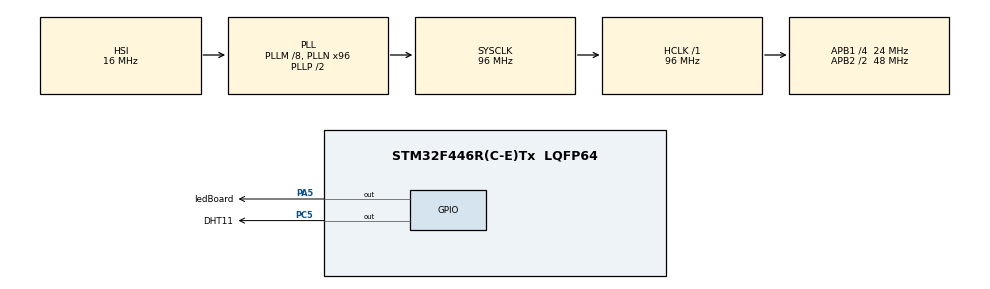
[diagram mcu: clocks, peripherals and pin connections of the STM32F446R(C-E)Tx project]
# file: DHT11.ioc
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Mcu.Family=STM32F4
Mcu.Name=STM32F446R(C-E)Tx
Mcu.Package=LQFP64
NVIC.PriorityGroup=NVIC_PRIORITYGROUP_4
NVIC.TIM6_DAC_IRQn=true\:0\:0\:false\:false\:true\:true\:true\:true
PA13.Mode=Serial_Wire
PA13.Signal=SYS_JTMS-SWDIO
PA14.Mode=Serial_Wire
PA14.Signal=SYS_JTCK-SWCLK
PA5.GPIO_Label=ledBoard
PA5.Signal=GPIO_Output
PC5.GPIO_Label=DHT11
PC5.GPIO_Speed=GPIO_SPEED_FREQ_VERY_HIGH
PC5.PinState=GPIO_PIN_RESET
PC5.Signal=GPIO_Output
ProjectManager.HeapSize=0x200
ProjectManager.StackSize=0x400
ProjectManager.TargetToolchain=STM32CubeIDE
RCC.AHBFreq_Value=96000000
RCC.APB1CLKDivider=RCC_HCLK_DIV4
RCC.APB1Freq_Value=24000000
RCC.APB1TimFreq_Value=48000000
RCC.APB2CLKDivider=RCC_HCLK_DIV2
RCC.APB2Freq_Value=48000000
RCC.APB2TimFreq_Value=96000000
RCC.CortexFreq_Value=96000000
RCC.HCLKFreq_Value=96000000
RCC.PLLM=8
RCC.PLLN=96
RCC.SYSCLKFreq_VALUE=96000000
RCC.SYSCLKSource=RCC_SYSCLKSOURCE_PLLCLK
RCC.USBFreq_Value=96000000
RCC.VCOOutputFreq_Value=192000000
TIM6.Period=1200-1
TIM6.Prescaler=48000-1
VP_TIM6_VS_ClockSourceINT.Mode=Enable_Timer
board=custom

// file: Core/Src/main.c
/* USER CODE BEGIN Header */
/**
 ******************************************************************************
 * @file           : main.c
 * @brief          : Main program body
 ******************************************************************************
 * @attention
 *
 * Copyright (c) 2022 STMicroelectronics.
 * All rights reserved.
 *
 * This software is licensed under terms that can be found in the LICENSE file
 * in the root directory of this software component.
 * If no LICENSE file comes with this software, it is provided AS-IS.
 *
 ******************************************************************************
 */
/* USER CODE END Header */
#include "main.h"

/* USER CODE BEGIN Includes */
#include "DHT11.h"
/* USER CODE END Includes */

TIM_HandleTypeDef htim6;

/* USER CODE BEGIN PV */
uint8_t temp, hum; // creo dos variables para leer los datos de T° y H

/* USER CODE END PV */

void SystemClock_Config(void);
static void MX_GPIO_Init(void);
static void MX_TIM6_Init(void);

int main(void)
{

  /* MCU Configuration--------------------------------------------------------*/

  /* Reset of all peripherals, Initializes the Flash interface and the Systick. */
  HAL_Init();

  /* Configure the system clock */
  SystemClock_Config();

  /* Initialize all configured peripherals */
  MX_GPIO_Init();
  MX_TIM6_Init();
  /* USER CODE BEGIN 2 */

  HAL_TIM_Base_Start_IT(&htim6);

  /* USER CODE END 2 */

  /* Infinite loop */
  /* USER CODE BEGIN WHILE */
	while (1) {

		if(hum>50){
			HAL_GPIO_TogglePin(ledBoard_GPIO_Port, ledBoard_Pin);
			HAL_Delay(250);
		}

    /* USER CODE END WHILE */

	}
}

void SystemClock_Config(void)
{
  RCC_OscInitTypeDef RCC_OscInitStruct = {0};
  RCC_ClkInitTypeDef RCC_ClkInitStruct = {0};

  /** Configure the main internal regulator output voltage
  */
  __HAL_RCC_PWR_CLK_ENABLE();
  __HAL_PWR_VOLTAGESCALING_CONFIG(PWR_REGULATOR_VOLTAGE_SCALE3);

  /** Initializes the RCC Oscillators according to the specified parameters
  * in the RCC_OscInitTypeDef structure.
  */
  RCC_OscInitStruct.OscillatorType = RCC_OSCILLATORTYPE_HSI;
  RCC_OscInitStruct.HSIState = RCC_HSI_ON;
  RCC_OscInitStruct.HSICalibrationValue = RCC_HSICALIBRATION_DEFAULT;
  RCC_OscInitStruct.PLL.PLLState = RCC_PLL_ON;
  RCC_OscInitStruct.PLL.PLLSource = RCC_PLLSOURCE_HSI;
  RCC_OscInitStruct.PLL.PLLM = 8;
  RCC_OscInitStruct.PLL.PLLN = 96;
  RCC_OscInitStruct.PLL.PLLP = RCC_PLLP_DIV2;
  RCC_OscInitStruct.PLL.PLLQ = 2;
  RCC_OscInitStruct.PLL.PLLR = 2;
  if (HAL_RCC_OscConfig(&RCC_OscInitStruct) != HAL_OK)
  {
    Error_Handler();
  }

  /** Initializes the CPU, AHB and APB buses clocks
  */
  RCC_ClkInitStruct.ClockType = RCC_CLOCKTYPE_HCLK|RCC_CLOCKTYPE_SYSCLK
                              |RCC_CLOCKTYPE_PCLK1|RCC_CLOCKTYPE_PCLK2;
  RCC_ClkInitStruct.SYSCLKSource = RCC_SYSCLKSOURCE_PLLCLK;
  RCC_ClkInitStruct.AHBCLKDivider = RCC_SYSCLK_DIV1;
  RCC_ClkInitStruct.APB1CLKDivider = RCC_HCLK_DIV4;
  RCC_ClkInitStruct.APB2CLKDivider = RCC_HCLK_DIV2;

  if (HAL_RCC_ClockConfig(&RCC_ClkInitStruct, FLASH_LATENCY_3) != HAL_OK)
  {
    Error_Handler();
  }
}

static void MX_TIM6_Init(void)
{

  TIM_MasterConfigTypeDef sMasterConfig = {0};

  htim6.Instance = TIM6;
  htim6.Init.Prescaler = 48000-1;
  htim6.Init.CounterMode = TIM_COUNTERMODE_UP;
  htim6.Init.Period = 1200-1;
  htim6.Init.AutoReloadPreload = TIM_AUTORELOAD_PRELOAD_DISABLE;
  if (HAL_TIM_Base_Init(&htim6) != HAL_OK)
  {
    Error_Handler();
  }
  sMasterConfig.MasterOutputTrigger = TIM_TRGO_RESET;
  sMasterConfig.MasterSlaveMode = TIM_MASTERSLAVEMODE_DISABLE;
  if (HAL_TIMEx_MasterConfigSynchronization(&htim6, &sMasterConfig) != HAL_OK)
  {
    Error_Handler();
  }

}

static void MX_GPIO_Init(void)
{
  GPIO_InitTypeDef GPIO_InitStruct = {0};

  /* GPIO Ports Clock Enable */
  __HAL_RCC_GPIOA_CLK_ENABLE();
  __HAL_RCC_GPIOC_CLK_ENABLE();

  /*Configure GPIO pin Output Level */
  HAL_GPIO_WritePin(ledBoard_GPIO_Port, ledBoard_Pin, GPIO_PIN_RESET);

  /*Configure GPIO pin Output Level */
  HAL_GPIO_WritePin(DHT11_GPIO_Port, DHT11_Pin, GPIO_PIN_RESET);

  /*Configure GPIO pin : ledBoard_Pin */
  GPIO_InitStruct.Pin = ledBoard_Pin;
  GPIO_InitStruct.Mode = GPIO_MODE_OUTPUT_PP;
  GPIO_InitStruct.Pull = GPIO_NOPULL;
  GPIO_InitStruct.Speed = GPIO_SPEED_FREQ_LOW;
  HAL_GPIO_Init(ledBoard_GPIO_Port, &GPIO_InitStruct);

  /*Configure GPIO pin : DHT11_Pin */
  GPIO_InitStruct.Pin = DHT11_Pin;
  GPIO_InitStruct.Mode = GPIO_MODE_OUTPUT_PP;
  GPIO_InitStruct.Pull = GPIO_NOPULL;
  GPIO_InitStruct.Speed = GPIO_SPEED_FREQ_VERY_HIGH;
  HAL_GPIO_Init(DHT11_GPIO_Port, &GPIO_InitStruct);

}

/* USER CODE BEGIN 4 */
void HAL_TIM_PeriodElapsedCallback(TIM_HandleTypeDef *htim) {
	if (htim->Instance == TIM6) {//Leemos el sensor cada 1200ms
		Leer_DHT11(&temp, &hum);
	}
}
/* USER CODE END 4 */

void Error_Handler(void)
{
	__disable_irq();
	while (1) {
	}
}
